# CH32H41X register map
Vendor: WCH Ltd.; File version: 1.2
Registers are 32-bit, read-write, reset 0x0 unless marked. A register's access mark holds for its fields unless they carry their own. Offsets are from the block's base; [hi:lo] are bit positions; {n}, {i} and the like mark numbered series.

## EMMC
Base 0x40024000
0x00 EMMC_ARGUMENT — SD 32bits command argument register
  [31:0] EMMC_ARGUMENT — 32 bit command parameter register
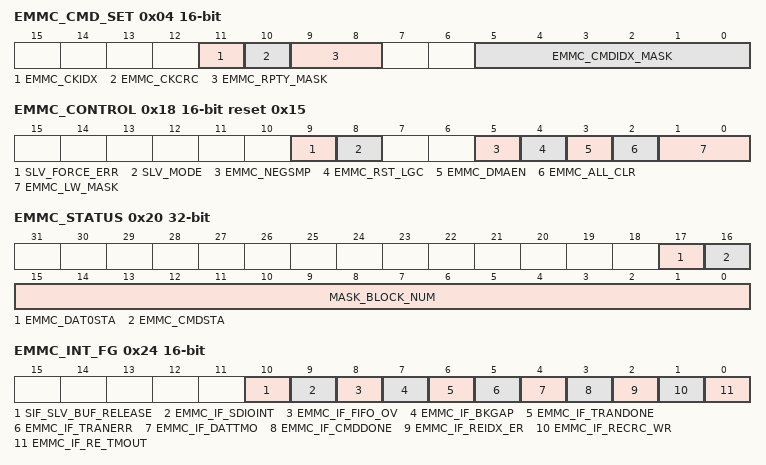
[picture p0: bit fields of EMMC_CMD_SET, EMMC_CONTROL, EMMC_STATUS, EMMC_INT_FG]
0x04 EMMC_CMD_SET 16-bit — SD 16bits cmd setting register
  [11] EMMC_CKIDX — check the response command index
  [10] EMMC_CKCRC — check the response CRC
  [9:8] EMMC_RPTY_MASK — current respone type
  [5:0] EMMC_CMDIDX_MASK — the index number of the currently sent command
{0x8+4i} EMMC_RESPONSE{i} ro (i=0..3) — SD 128bits response register, [{32i+31}:{32i}] 32bits
  [31:0] EMMC_RESPONSE{i} — response parameter register
0x14 EMMC_WRITE_CONT wo (alternate view of EMMC_RESPONSE3) — Multiplexing register of the EMMC_RESPONSE3,[127:96] 32bits
  [31:0] EMMC_WRITE_CONT — response parameter register
0x18 EMMC_CONTROL 16-bit reset 0x15 — SD 8 bits control register
  [9] SLV_FORCE_ERR — Software forced data block CRC error in slave mode
  [8] SLV_MODE — enable Slave mode
  [5] EMMC_NEGSMP — controller use nagedge sample cmd
  [4] EMMC_RST_LGC — reset the data tran/recv logic
  [3] EMMC_DMAEN — enable the dma
  [2] EMMC_ALL_CLR — reset all the inner logic, default is valid
  [1:0] EMMC_LW_MASK — effctive data width for sending or receiving data
0x1C EMMC_TIMEOUT 8-bit reset 0xC — SD 8 bits data timeout value
  [3:0] EMMC_TOCNT_MASK — response data timeout configuration
0x20 EMMC_STATUS ro — SD status
  [17] EMMC_DAT0STA — indicate dat[0] line is high level now
  [16] EMMC_CMDSTA — indicate cmd line is high level now
  [15:0] MASK_BLOCK_NUM — the number of blocks successfully transmitted in the current multi-block transmission
0x24 EMMC_INT_FG 16-bit — SD 16bits interrupt flag register
  [10] SIF_SLV_BUF_RELEASE — In slave double buffer mode,BUF releases the flag bit
  [9] EMMC_IF_SDIOINT — interrupt from SDIO card inside
  [8] EMMC_IF_FIFO_OV — fifo overflow, when write sd, indicate empty overflow, when read sd, indicate full overflow
  [7] EMMC_IF_BKGAP — every block gap interrupt when multiple read/write, allow drive change the DMA address at this moment
  [6] EMMC_IF_TRANDONE — all the blocks have been tran/recv successfully
  [5] EMMC_IF_TRANERR — last block have encountered a CRC error
  [4] EMMC_IF_DATTMO — data line busy timeout
  [3] EMMC_IF_CMDDONE — when cmd hasn't response, indicate cmd has been sent, when cmd has a response, indicate cmd has bee sent and has received the response
  [2] EMMC_IF_REIDX_ER — indicate INDEX error of the response
  [1] EMMC_IF_RECRC_WR — indicate CRC error of the response
  [0] EMMC_IF_RE_TMOUT — indicate when expect the response, timeout
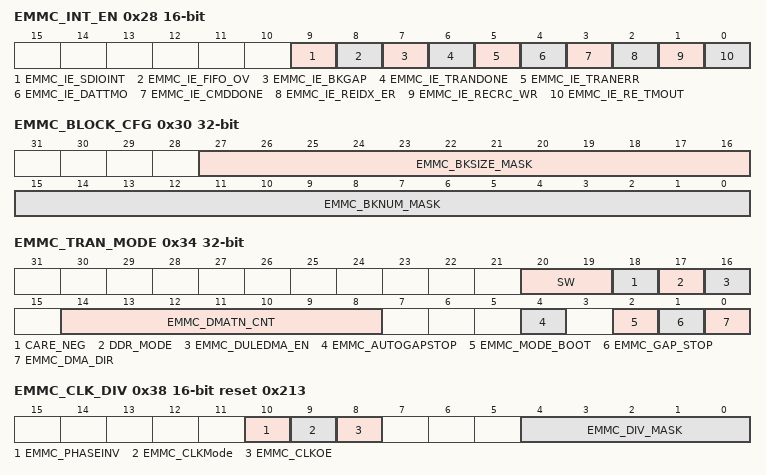
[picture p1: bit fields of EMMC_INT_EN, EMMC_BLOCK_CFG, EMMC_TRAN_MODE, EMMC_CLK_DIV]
0x28 EMMC_INT_EN 16-bit — SD 16bits interrupt enable register
  [9] EMMC_IE_SDIOINT — SDIO card interrupt enable
  [8] EMMC_IE_FIFO_OV — FIFO overflow interrupt enable
  [7] EMMC_IE_BKGAP — single block transmission completion interrupt enable
  [6] EMMC_IE_TRANDONE — all blocks transfer complete interrupt enable
  [5] EMMC_IE_TRANERR — blocks transfer CRC error interrupt enable
  [4] EMMC_IE_DATTMO — data timeout interrupt enable
  [3] EMMC_IE_CMDDONE — command completion interrupt enable
  [2] EMMC_IE_REIDX_ER — response index check error interrupt enable
  [1] EMMC_IE_RECRC_WR — response CRC check error interrupt enable
  [0] EMMC_IE_RE_TMOUT — command response timeout interrupt enable
0x2C EMMC_DMA_BEG1 — SD 32 bits DMA start address register when to operate
  [31:0] EMMC_DMAAD1_MASK — start address of read-write data buffer,the lower 4 bits are fixed to 0
0x30 EMMC_BLOCK_CFG — SD 32bits data counter, [15:0] number of blocks this time will tran/recv, [27:16] block sise(byte number) of every block in this time tran/recv
  [27:16] EMMC_BKSIZE_MASK — single block transfer size
  [15:0] EMMC_BKNUM_MASK — the number of blocks to be transferred
0x34 EMMC_TRAN_MODE — SD TRANSFER MODE register
  [20:19] SW — In DDR mode,the clock is switched
  [18] CARE_NEG — In DDR mode,check the falling edge of the clock
  [17] DDR_MODE — enable DDR mode
  [16] EMMC_DULEDMA_EN — enable double buffer dma
  [14:8] EMMC_DMATN_CNT — in double buffer mode,set the block count value of buffer switch
  [4] EMMC_AUTOGAPSTOP — enable auto set bTM_GAP_STOP when tran start
  [2] EMMC_MODE_BOOT — enable emmc boot mode
  [1] EMMC_GAP_STOP — clock stop mode after block completion
  [0] EMMC_DMA_DIR — set DMA direction is controller to emmc card
0x38 EMMC_CLK_DIV 16-bit reset 0x213 — SD clock divider register
  [10] EMMC_PHASEINV — invert chip output sdclk phase
  [9] EMMC_CLKMode — EMMC clock frequency mode selection bit
  [8] EMMC_CLKOE — chip output sdclk oe
  [4:0] EMMC_DIV_MASK — clk div
0x3C EMMC_DMA_BEG2 — SD 32bits DMA start address register when to operate
  [31:0] EMMC_DMAAD2_MASK — start address of read-write data buffer,the lower 4 bits are fixed to 0
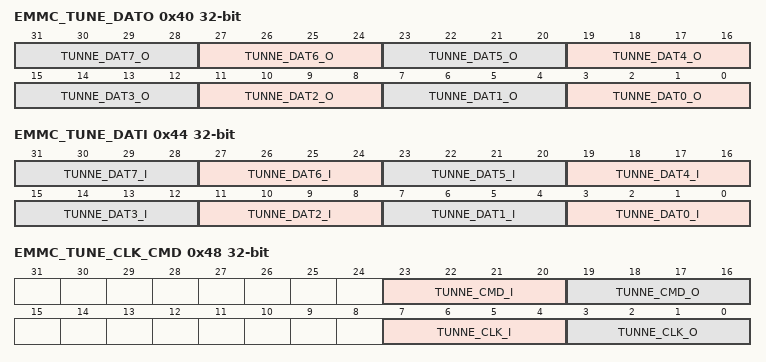
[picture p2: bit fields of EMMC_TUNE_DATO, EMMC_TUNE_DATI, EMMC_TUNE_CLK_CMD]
0x40 EMMC_TUNE_DATO — data output delay register
  [4n+3:4n] TUNNE_DAT{n}_O (n=0..7) — the delay of data {n} output
0x44 EMMC_TUNE_DATI — data input delay register
  [4n+3:4n] TUNNE_DAT{n}_I (n=0..7) — In DDR mode,the delay of data {n} input
0x48 EMMC_TUNE_CLK_CMD — clock and command delay registers
  [23:20] TUNNE_CMD_I — In DDR mode,the delay of the clock output
  [19:16] TUNNE_CMD_O — In DDR mode,the delay of the clock input
  [7:4] TUNNE_CLK_I — In DDR mode,delay in command output
  [3:0] TUNNE_CLK_O — In DDR mode,delay in command input
